# nrf9120_MLM1 register map
Vendor: Nordic Semiconductor; Series: nrf91; File version: 1
CPU: CM4 r0p1, little endian, MPU, FPU, 3 interrupt priority bits
Registers are 32-bit, read-write, reset 0x0 unless marked. A register's access mark holds for its fields unless they carry their own. Offsets are from the block's base; [hi:lo] are bit positions; lines under a group give offsets from that group; {n}, {i} and the like mark numbered series; 'fields as' and 'values as' point back to an identical list.

## FICR — Factory Information Configuration Registers
Base 0x00FF0000
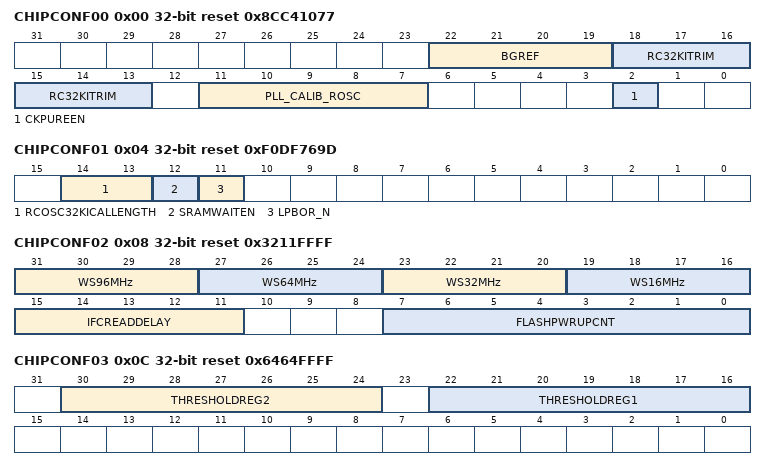
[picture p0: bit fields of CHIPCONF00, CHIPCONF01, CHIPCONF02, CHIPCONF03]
0x00 CHIPCONF00 ro reset 0x8CC41077 — Miscellaneous analog configuration. Will be set during production test.
  [22:19] BGREF — Bandgap-reference trim code
  [18:13] RC32KITRIM — 32.768 kHz RC-oscillator trim code
  [11:7] PLL_CALIB_ROSC — HFCLK ring oscillator trim codes. Previous name: HFROSCTRIM.
  [2] CKPUREEN — Enable clock gate in clock purifier. Should always be 1.
0x04 CHIPCONF01 ro reset 0xF0DF769D — Miscellaneous analog configuration. Will be set during production test.
  [14:13] RCOSC32KICALLENGTH — 32kHz RC oscillator calibration length
  [12] SRAMWAITEN — Enable wait on ready upon accessing SRAM when turned on
  [11] LPBOR_N — Enable low power BOR. Active low.
0x08 CHIPCONF02 ro reset 0x3211FFFF — Miscellaneous analog configuration. Will be set during production test.
  [31:28] WS96MHz — wait-states (excluding the cache controller) for I-Code flash access (HFCLOCK = 96 MHz). D-Code has one more wait-state.
    {v}={v}WS ({v} wait-state in total for I-Code ({v+1} for D-Code)) (v=1..4)
  [27:24] WS64MHz — wait-states (excluding the cache controller) for I-Code flash access (HFCLOCK = 64 MHz). D-Code has one more wait-state.
    values as WS96MHz
  [23:20] WS32MHz — wait-states (excluding the cache controller) for I-Code flash access (HFCLOCK = 32 MHz). D-Code has one more wait-state.
    values as WS96MHz
  [19:16] WS16MHz — wait-states (excluding the cache controller) for I-Code flash access (HFCLOCK = 16 MHz), D-Code has one more wait-state.
    values as WS96MHz
  [15:11] IFCREADDELAY — number of cycles before Information Configuration Registers can be read
  [7:0] FLASHPWRUPCNT — Number of successful FLASHPWRUPn read cycles when powering up flash. After chip power up, the NVMC controller reads FLASHPWRUPn for 7 us.
0x0C CHIPCONF03 ro reset 0x6464FFFF — Miscellaneous analog configuration. Will be set during production test.
  [30:24] THRESHOLDREG2 — Sets the threshold value of power regulator (default value for POWER->THRESHOLDREG2)
  [22:16] THRESHOLDREG1 — Sets the threshold value of power regulator (default value for POWER->THRESHOLDREG1)
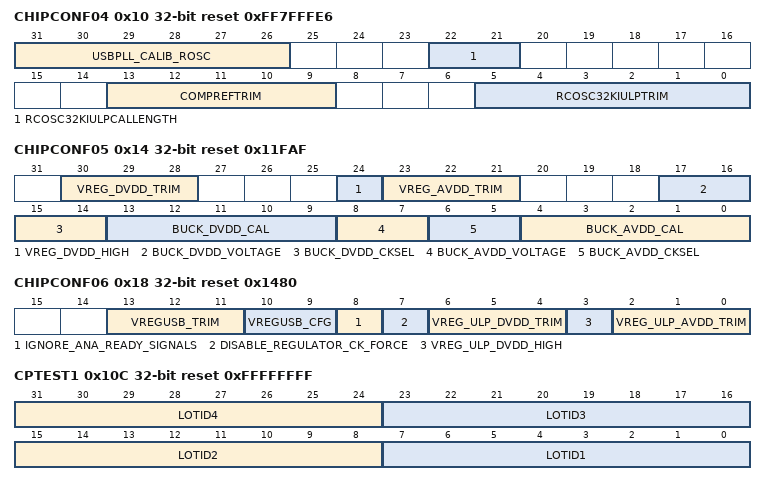
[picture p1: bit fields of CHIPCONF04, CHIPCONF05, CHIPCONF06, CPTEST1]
0x10 CHIPCONF04 ro reset 0xFF7FFFE6 — Miscellaneous analog configuration. Will be set during production test.
  [31:26] USBPLL_CALIB_ROSC — USB 48 MHz ring oscillator trim codes.
  [22:21] RCOSC32KIULPCALLENGTH — 32kHz ULP RC oscillator calibration length
  [13:9] COMPREFTRIM — Calibrate internal bandgap reference in COMP
  [5:0] RCOSC32KIULPTRIM — 32.678 kHz ULP RC oscillator trim code
0x14 CHIPCONF05 ro reset 0x11FAF — Miscellaneous analog configuration. Will be set during production test.
  [30:28] VREG_DVDD_TRIM — VREG DVDD Output voltage calibration
    0=default voltage
  [24] VREG_DVDD_HIGH — Enable or disable the feature
    0=Disabled (Nominal output levels of VREG_DVDD LDO); 1=Enabled (Increased output levels of VREG_DVDD LDO)
  [23:21] VREG_AVDD_TRIM — VREG AVDD Output voltage calibration
    0=default voltage
  [17:16] BUCK_DVDD_VOLTAGE — BUCK_DVDD Output voltage selection.
    0=1V00 (1.00 V); 1=1V09 (1.09 V); 2=1V17 (1.17 V); 3=1V26 (1.26 V)
  [15:14] BUCK_DVDD_CKSEL — BUCK DVDD Input clock selection.
    0=NORMAL (normal clock); 1=INVERTED (inverted clock)
  [13:9] BUCK_DVDD_CAL — BUCK DVDD output voltage calibration
  [8:7] BUCK_AVDD_VOLTAGE — Output voltage selection.
    values as BUCK_DVDD_VOLTAGE
  [6:5] BUCK_AVDD_CKSEL — BUCK AVDD Input clock selection.
    0=NORMAL (normal clock); 1=INVERTED (inverted clock)
  [4:0] BUCK_AVDD_CAL — BUCK AVDD output voltage calibration
0x18 CHIPCONF06 ro reset 0x1480 — Miscellaneous analog configuration. Will be set during production test.
  [13:11] VREGUSB_TRIM — VREG USB Output voltage calibration
    0=min voltage; 7=max voltage
  [10:9] VREGUSB_CFG — VREG USB Configuration
  [8] IGNORE_ANA_READY_SIGNALS — Ignore Reday Signal from Analog part
    0=Power regulator control waits for analog ready signals (normal mode); 1=Power regulator control does not wait for analog ready signals (backdoor)
  [7] DISABLE_REGULATOR_CK_FORCE — Disable Regulator to Force Clock
    1=Power regulator control requests clock automatically when it needs it (normal mode); 0=Power regulator control requests clock constantly (backdoor)
  [6:4] VREG_ULP_DVDD_TRIM — VREG ULP DVDD Output voltage calibration
    0=min voltage; 7=max voltage
  [3] VREG_ULP_DVDD_HIGH — Enable or disable the feature
    0=Disabled (Nominal output levels of VREG_ULP_DVDD LDO); 1=Enabled (Increased output levels of VREG_ULP_DVDD LDO)
  [2:0] VREG_ULP_AVDD_TRIM — VREG ULP AVDD Output voltage calibration
    0=min voltage; 7=max voltage
{0xF0+4i} FLASHPWRUP{i} ro reset 0xAAAAAAAA (i=0..3) — Power-up pattern for flash
0x100 RAM ro reset 0x40 — RAM variant
  [31:0] RAM
    16=K16 (16 kByte RAM); 32=K32 (32 kByte RAM); 64=K64 (64 kByte RAM); 0xFFFFFFFF=Unspecified
0x100 TESTSTATUS ro reset 0xFFFFFFFF (alternate view of RAM) — Code memory test status. Will be set during production test.
0x104 FLASH ro reset 0x400 — Flash variant
  [31:0] FLASH
    128=K128 (128 kByte FLASH); 0x100=K256 (256 kByte FLASH); 0x200=K512 (512 kByte FLASH); 0x400=K1024 (1 MByte FLASH); 0xFFFFFFFF=Unspecified
0x104 CPTEST0 ro reset 0xFFFFFFFF (alternate view of FLASH) — Result from Circuit Probe test
  [31:0] CP1
0x108 CPTEST00 ro reset 0xFFFFFFFF — Result from Circuit Probe test
  [31:0] CP1
0x10C CPTEST1 ro reset 0xFFFFFFFF — Result from Circuit Probe test
  [31:24] LOTID4 — 4th ascii byte of Lot ID character
  [23:16] LOTID3 — 3rd ascii byte of Lot ID character
  [15:8] LOTID2 — 2nd ascii byte of Lot ID character
  [7:0] LOTID1 — 1st ascii byte of Lot ID character
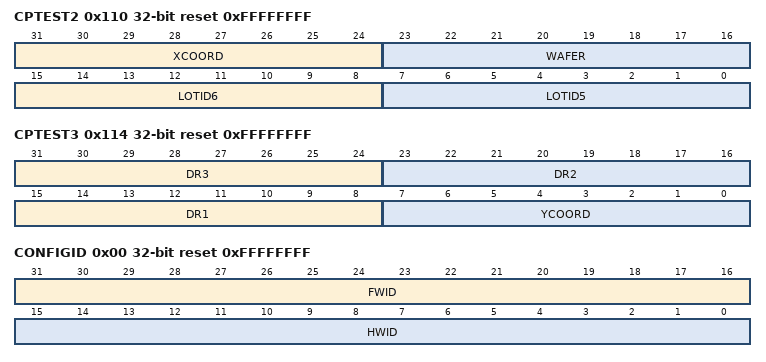
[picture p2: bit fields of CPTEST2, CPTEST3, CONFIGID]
0x110 CPTEST2 ro reset 0xFFFFFFFF — Result from Circuit Probe test
  [31:24] XCOORD — Device X-coordinate, always >=0, offset so that the leftmost value on wafer is 0
  [23:16] WAFER — Wafer number, 1 byte integer
  [15:8] LOTID6 — 6th ascii byte of Lot ID character
  [7:0] LOTID5 — 5th ascii byte of Lot ID character
0x114 CPTEST3 ro reset 0xFFFFFFFF — Result from Circuit Probe test
  [31:24] DR3 — Data Retention (DR) flag
  [23:16] DR2 — Data Retention (DR) flag
  [15:8] DR1 — Data Retention (DR) flag
  [7:0] YCOORD — Device Y-coordinate, always >=0, offset so that the bottom value on wafer is 0
0x118 CPTEST4 ro reset 0xFFFFFFFF — Result from Circuit Probe test
  [7:0] DR4 — Data Retention (DR) flag
{0x108+4i} CPTEST{i} ro reset 0xFFFFFFFF (i=5..8) — Result from Circuit Probe test, flash repair information
  [31:0] CPTEST{i} — flash repair information
0x200 INFO group — Device info
  0x00 CONFIGID ro reset 0xFFFFFFFF — Configuration identifier
    [31:16] FWID — Deprecated field - Identification number for the FW that is pre-loaded into the chip
    [15:0] HWID — Identification number for the HW
  {0x4+4j} DEVICEID[{j}] (j=0..1) ro reset 0xFFFFFFFF — Description collection[0]: Device identifier
    [31:0] DEVICEID — 64 bit unique device identifier
  0x0C PART ro reset 0x91200 — Part code
    [31:0] PART
      0xFFFFFFFF=Unspecified
  0x10 VARIANT ro reset 0x41414142 — Part Variant, Hardware version and Production configuration
    [31:0] VARIANT — Part Variant, Hardware version and Production configuration, encoded as ASCII
      0xFFFFFFFF=Unspecified
  0x14 PACKAGE ro reset 0x2000 — Package option
    [31:0] PACKAGE
      0xFFFFFFFF=Unspecified
  0x18 RAM ro reset 0x40 — RAM variant
    fields as RAM
  0x1C FLASH ro reset 0x400 — Flash variant
    fields as FLASH
  0x20 CODEPAGESIZE ro reset 0xFFFFFFFF — Code memory page size
  0x24 CODESIZE ro reset 0xFFFFFFFF — Code memory size
    [31:0] CODESIZE — Code memory size in number of pages
  0x28 DEVICETYPE ro reset 0xFFFFFFFF
    [31:0] DEVICETYPE
      0=Die (Device is an physical DIE); 0xFFFFFFFF=FPGA (Device is an FPGA)
{0x300+8i} TRIMCNF[{i}] (i=0..31) group — Unspecified
  0x00 ADDR ro — Description cluster[0]: Address
    [31:0] Address
  0x04 DATA ro — Description cluster[0]: Data
